AUTOSAR XML (schema 00050)
package /Components
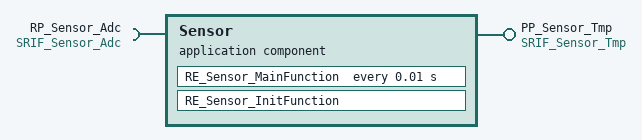
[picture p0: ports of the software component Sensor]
  application sw component type Sensor
    require port RP_Sensor_Adc: nonqueued-receiver-com-spec{data-element=Adc_Value, init-value=0}, required-interface=SRIF_Sensor_Adc
    provide port PP_Sensor_Tmp: nonqueued-sender-com-spec{data-element=Tmp_Value, init-value=0}, provided-interface=SRIF_Sensor_Tmp
    behavior Sensor_IB: handle-termination-and-restart=NO-SUPPORT
      timing event TE_Sensor_MainFunction: start-on-event=RE_Sensor_MainFunction, period=0.01
      runnable RE_Sensor_MainFunction
        data-read-access:
          access IN_RP_Sensor_Adc_Adc_Value: accessed-variable=RP_Sensor_Adc.Adc_Value
        data-write-access:
          access OUT_PP_Sensor_Tmp_Tmp_Value: accessed-variable=PP_Sensor_Tmp.Tmp_Value
      runnable RE_Sensor_InitFunction
